AUTOSAR XML (schema 00048)
package /VehicleProject
  system System
package /NM
  nm config NmConfig: can-nm-cluster-coupling=coupled-cluster=[TC37X_VCU_CAN00_CAN, TC37X_VCU_CAN01_CAN]
    can nm cluster TC37X_VCU_CAN00_CAN: communication-cluster=TC37X_VCU_CAN00, nm-channel-id=0, nm-msg-cycle-time=0.5, nm-network-timeout=2, nm-repeat-message-time=1.5, nm-user-data-length=6, nm-wait-bus-sleep-time=2
      can nm node GWM: nm-if-ecu=GWM_CAN, nm-node-id=28, rx-nm-pdu=VCU_Tx_51Ch_NM_oTC37X_VCU_CAN00, tx-nm-pdu=VCU_Rx_500h_NM_oTC37X_VCU_CAN00, nm-msg-cycle-offset=0, nm-msg-reduced-time=0.32, nm-range-config={lower-can-id=1024, upper-can-id=1151}
      can nm node Tester: nm-if-ecu=Tester_CAN, nm-node-id=28, nm-passive-mode-enabled=true, nm-msg-cycle-offset=0, nm-msg-reduced-time=0.32, nm-range-config={lower-can-id=1024, upper-can-id=1151}
      can nm node VCU: controller=CT_TC37X_VCU_CAN00, nm-if-ecu=VCU_CAN, nm-node-id=28, rx-nm-pdu=VCU_Rx_500h_NM_oTC37X_VCU_CAN00, tx-nm-pdu=VCU_Tx_51Ch_NM_oTC37X_VCU_CAN00, nm-msg-cycle-offset=0, nm-msg-reduced-time=0.32, nm-range-config={lower-can-id=1024, upper-can-id=1151}
    can nm cluster TC37X_VCU_CAN01_CAN: communication-cluster=TC37X_VCU_CAN01, nm-channel-id=1, nm-msg-cycle-time=0.5, nm-network-timeout=2, nm-repeat-message-time=1.5, nm-user-data-length=6, nm-wait-bus-sleep-time=2
      can nm node GWM: nm-if-ecu=GWM_CAN, nm-node-id=28, rx-nm-pdu=VCU_Tx_51Ch_NM_oTC37X_VCU_CAN01, tx-nm-pdu=VCU_Rx_500h_NM_oTC37X_VCU_CAN01, nm-msg-cycle-offset=0, nm-msg-reduced-time=0.32, nm-range-config={lower-can-id=1024, upper-can-id=1151}
      can nm node Tester: nm-if-ecu=Tester_CAN, nm-node-id=28, nm-passive-mode-enabled=true, nm-msg-cycle-offset=0, nm-msg-reduced-time=0.32, nm-range-config={lower-can-id=1024, upper-can-id=1151}
      can nm node VCU: controller=CT_TC37X_VCU_CAN01, nm-if-ecu=VCU_CAN, nm-node-id=28, rx-nm-pdu=VCU_Rx_500h_NM_oTC37X_VCU_CAN01, tx-nm-pdu=VCU_Tx_51Ch_NM_oTC37X_VCU_CAN01, nm-msg-cycle-offset=0, nm-msg-reduced-time=0.32, nm-range-config={lower-can-id=1024, upper-can-id=1151}
    nm-if-ecus:
      nm ecu GWM_CAN: nm-node-id-enabled=true, nm-user-data-enabled=true
      nm ecu Tester_CAN: nm-node-id-enabled=true, nm-passive-mode-enabled=true, nm-user-data-enabled=true
      nm ecu VCU_CAN: ecu-instance=VCU, nm-node-id-enabled=true, nm-user-data-enabled=true
package /TP
  can tp config TC37X_VCU_CAN00_CAN: communication-cluster=TC37X_VCU_CAN00, can-tp-ecu{cycle-time-main-function=0.005, ecu-instance=VCU}
    can tp channel TPCH: channel-id=0, channel-mode=FULL-DUPLEX-MODE
    can-tp-connection addressing-format=STANDARD, can-tp-channel=TPCH, data-pdu=Vcu_Uds_Func_Request_Tp_oTC37X_VCU_CAN00, receiver=TN_VCU, ta-type=FUNCTIONAL, tp-sdu=Vcu_Uds_Func_Request_oTC37X_VCU_CAN00, transmitter=TN_Tester:
      ident Vcu_Uds_Func_Request_oTN_Tester
    can-tp-connection addressing-format=STANDARD, can-tp-channel=TPCH, data-pdu=Vcu_Uds_Phy_Request_Tp_oTC37X_VCU_CAN00, flow-control-pdu=Vcu_Uds_Response_Tp_oTC37X_VCU_CAN00, receiver=TN_VCU, ta-type=PHYSICAL, tp-sdu=Vcu_Uds_Phy_Request_oTC37X_VCU_CAN00, transmitter=TN_Tester:
      ident Vcu_Uds_Phy_Request_oTN_VCU
    can-tp-connection addressing-format=STANDARD, can-tp-channel=TPCH, data-pdu=Vcu_Uds_Response_Tp_oTC37X_VCU_CAN00, flow-control-pdu=Vcu_Uds_Phy_Request_Tp_oTC37X_VCU_CAN00, receiver=TN_Tester, ta-type=PHYSICAL, tp-sdu=Vcu_Uds_Response_oTC37X_VCU_CAN00, transmitter=TN_VCU:
      ident Vcu_Uds_Response_oTN_VCU
    can tp node TN_Tester
    can tp node TN_VCU: connector=CN_TC37X_VCU_CAN00
  lin tp config LIN00: communication-cluster=LIN00
    tp address TA_0x0052: tp-address=82
    tp address TA_0x007E: tp-address=126
    tp-connections:
      data-pdu=MasterReq_Tp_oLIN00, lin-tp-n-sdu=MasterReq_oLIN00, multicast=TA_0x007E, receiver=TN_0x0052_GWM, transmitter=TN_Master
      data-pdu=SlaveResp_Tp_oLIN00, flow-control=MasterReq_Tp_oLIN00, lin-tp-n-sdu=SlaveResp_GWM_oLIN00, receiver=TN_Master, transmitter=TN_0x0052_GWM
      data-pdu=MasterReq_Tp_oLIN00, flow-control=SlaveResp_Tp_oLIN00, lin-tp-n-sdu=MasterReq_GWM_oLIN00, receiver=TN_0x0052_GWM, transmitter=TN_Master
    lin tp node TN_0x0052_GWM: tp-address=TA_0x0052
    lin tp node TN_Master: connector=CN_LIN00
package /Cluster
  can cluster TC37X_VCU_CAN00: baudrate=500000, protocol-name=CAN  # VCU_CAN00
    can physical channel CHNL: comm-connectors=CN_TC37X_VCU_CAN00
      frame VCU_Rx_500h_NM_oTC37X_VCU_CAN00: id 0x500, to VCU, frame-length=8, can-addressing-mode=STANDARD
        nm pdu VCU_Rx_500h_NM_oTC37X_VCU_CAN00: length=8, unused-bit-pattern=0
      frame VCU_Tx_51Ch_NM_oTC37X_VCU_CAN00: id 0x51C, from VCU, frame-length=8, can-addressing-mode=STANDARD
        nm pdu VCU_Tx_51Ch_NM_oTC37X_VCU_CAN00: length=8, unused-bit-pattern=0
      frame Vcu_Uds_Func_Request_oTC37X_VCU_CAN00: id 0x700, to VCU, frame-length=8, can-addressing-mode=STANDARD
        n pdu Vcu_Uds_Func_Request_Tp_oTC37X_VCU_CAN00: length=8
      frame Vcu_Uds_Phy_Request_oTC37X_VCU_CAN00: id 0x701, to VCU, frame-length=8, can-addressing-mode=STANDARD
        n pdu Vcu_Uds_Phy_Request_Tp_oTC37X_VCU_CAN00: length=8
      frame Vcu_Uds_Response_oTC37X_VCU_CAN00: id 0x781, from VCU, frame-length=8, can-addressing-mode=STANDARD
        n pdu Vcu_Uds_Response_Tp_oTC37X_VCU_CAN00: length=8
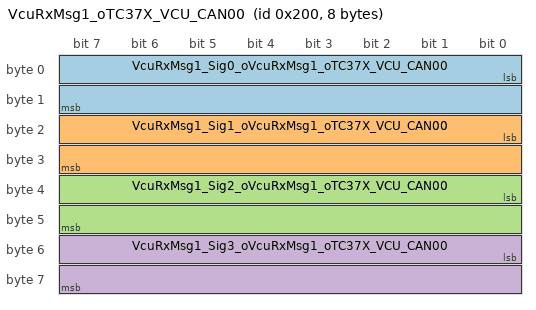
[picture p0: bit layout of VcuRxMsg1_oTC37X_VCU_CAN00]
      frame VcuRxMsg1_oTC37X_VCU_CAN00: id 0x200, to VCU, frame-length=8, can-addressing-mode=STANDARD
        pdu VcuRxMsg1_oTC37X_VCU_CAN00: length=8, minimum-delay=0, transmission-mode-false-timing=cyclic-timing={time-offset=0, time-period=0.5}, transmission-mode-true-timing=cyclic-timing={time-offset=0, time-period=0.5}, unused-bit-pattern=0
          signal VcuRxMsg1_Sig0_oVcuRxMsg1_oTC37X_VCU_CAN00: start 0, 16 bit, little-endian, i-signal-type=PRIMITIVE, init-value=0, base-type=sint16, compu-method=CM_VcuRxMsg1_Sig0, data-constr=DC_VcuRxMsg1_Sig0, transfer-property=PENDING, to VCU
          signal VcuRxMsg1_Sig1_oVcuRxMsg1_oTC37X_VCU_CAN00: start 16, 16 bit, little-endian, i-signal-type=PRIMITIVE, init-value=0, base-type=sint16, compu-method=CM_VcuRxMsg1_Sig1, data-constr=DC_VcuRxMsg1_Sig1, transfer-property=PENDING, to VCU
          signal VcuRxMsg1_Sig2_oVcuRxMsg1_oTC37X_VCU_CAN00: start 32, 16 bit, little-endian, i-signal-type=PRIMITIVE, init-value=0, base-type=sint16, compu-method=CM_VcuRxMsg1_Sig2, data-constr=DC_VcuRxMsg1_Sig2, transfer-property=PENDING, to VCU
          signal VcuRxMsg1_Sig3_oVcuRxMsg1_oTC37X_VCU_CAN00: start 48, 16 bit, little-endian, i-signal-type=PRIMITIVE, init-value=0, base-type=sint16, compu-method=CM_VcuRxMsg1_Sig3, data-constr=DC_VcuRxMsg1_Sig3, transfer-property=PENDING, to VCU
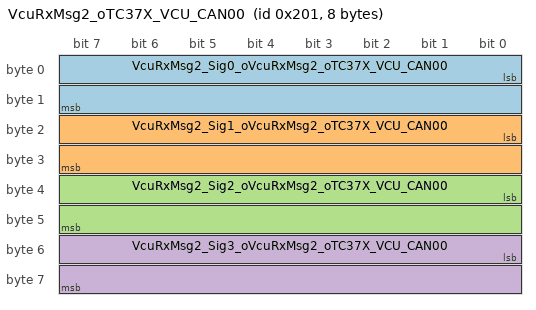
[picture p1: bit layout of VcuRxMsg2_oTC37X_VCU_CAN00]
      frame VcuRxMsg2_oTC37X_VCU_CAN00: id 0x201, to VCU, frame-length=8, can-addressing-mode=STANDARD
        pdu VcuRxMsg2_oTC37X_VCU_CAN00: length=8, minimum-delay=0, transmission-mode-false-timing=cyclic-timing={time-offset=0, time-period=0.5}, transmission-mode-true-timing=cyclic-timing={time-offset=0, time-period=0.5}, unused-bit-pattern=0
          signal VcuRxMsg2_Sig0_oVcuRxMsg2_oTC37X_VCU_CAN00: start 0, 16 bit, little-endian, i-signal-type=PRIMITIVE, init-value=0, base-type=sint16, compu-method=CM_VcuRxMsg2_Sig0, data-constr=DC_VcuRxMsg2_Sig0, transfer-property=PENDING, to VCU
          signal VcuRxMsg2_Sig1_oVcuRxMsg2_oTC37X_VCU_CAN00: start 16, 16 bit, little-endian, i-signal-type=PRIMITIVE, init-value=0, base-type=sint16, compu-method=CM_VcuRxMsg2_Sig1, data-constr=DC_VcuRxMsg2_Sig1, transfer-property=PENDING, to VCU
          signal VcuRxMsg2_Sig2_oVcuRxMsg2_oTC37X_VCU_CAN00: start 32, 16 bit, little-endian, i-signal-type=PRIMITIVE, init-value=0, base-type=sint16, compu-method=CM_VcuRxMsg2_Sig2, data-constr=DC_VcuRxMsg2_Sig2, transfer-property=PENDING, to VCU
          signal VcuRxMsg2_Sig3_oVcuRxMsg2_oTC37X_VCU_CAN00: start 48, 16 bit, little-endian, i-signal-type=PRIMITIVE, init-value=0, base-type=sint16, compu-method=CM_VcuRxMsg2_Sig3, data-constr=DC_VcuRxMsg2_Sig3, transfer-property=PENDING, to VCU
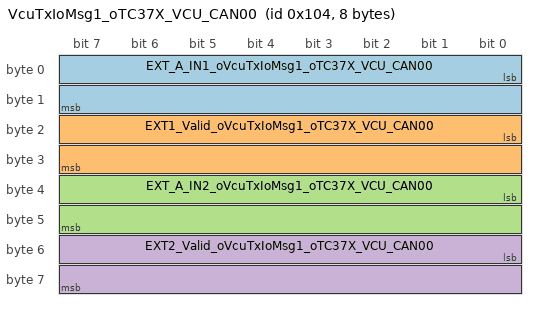
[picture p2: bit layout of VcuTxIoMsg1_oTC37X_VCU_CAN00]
      frame VcuTxIoMsg1_oTC37X_VCU_CAN00: id 0x104, from VCU, frame-length=8, can-addressing-mode=STANDARD
        pdu VcuTxIoMsg1_oTC37X_VCU_CAN00: length=8, minimum-delay=0, transmission-mode-false-timing=cyclic-timing={time-offset=0, time-period=0.5}, transmission-mode-true-timing=cyclic-timing={time-offset=0, time-period=0.5}, unused-bit-pattern=0
          signal EXT_A_IN1_oVcuTxIoMsg1_oTC37X_VCU_CAN00: start 0, 16 bit, little-endian, i-signal-type=PRIMITIVE, init-value=0, base-type=sint16, compu-method=CM_EXT_A_IN1, data-constr=DC_EXT_A_IN1, unit=U_C, transfer-property=PENDING
          signal EXT1_Valid_oVcuTxIoMsg1_oTC37X_VCU_CAN00: start 16, 16 bit, little-endian, i-signal-type=PRIMITIVE, init-value=0, base-type=uint16, compu-method=CM_EXT1_Valid, data-constr=DC_EXT1_Valid, transfer-property=PENDING
          signal EXT_A_IN2_oVcuTxIoMsg1_oTC37X_VCU_CAN00: start 32, 16 bit, little-endian, i-signal-type=PRIMITIVE, init-value=0, base-type=sint16, compu-method=CM_EXT_A_IN2, data-constr=DC_EXT_A_IN2, unit=U_C, transfer-property=PENDING
          signal EXT2_Valid_oVcuTxIoMsg1_oTC37X_VCU_CAN00: start 48, 16 bit, little-endian, i-signal-type=PRIMITIVE, init-value=0, base-type=uint16, compu-method=CM_EXT2_Valid, data-constr=DC_EXT2_Valid, transfer-property=PENDING
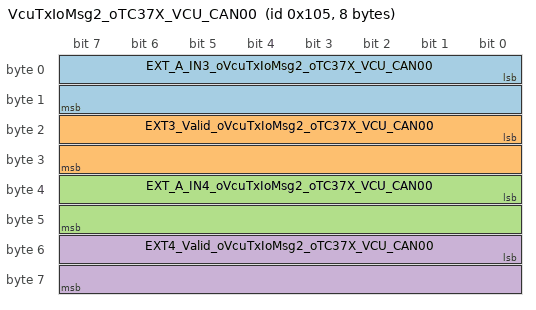
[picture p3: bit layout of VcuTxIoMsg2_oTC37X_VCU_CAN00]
      frame VcuTxIoMsg2_oTC37X_VCU_CAN00: id 0x105, from VCU, frame-length=8, can-addressing-mode=STANDARD
        pdu VcuTxIoMsg2_oTC37X_VCU_CAN00: length=8, minimum-delay=0, transmission-mode-false-timing=cyclic-timing={time-offset=0, time-period=0.5}, transmission-mode-true-timing=cyclic-timing={time-offset=0, time-period=0.5}, unused-bit-pattern=0
          signal EXT_A_IN3_oVcuTxIoMsg2_oTC37X_VCU_CAN00: start 0, 16 bit, little-endian, i-signal-type=PRIMITIVE, init-value=0, base-type=sint16, compu-method=CM_EXT_A_IN3, data-constr=DC_EXT_A_IN3, unit=U_C, transfer-property=PENDING
          signal EXT3_Valid_oVcuTxIoMsg2_oTC37X_VCU_CAN00: start 16, 16 bit, little-endian, i-signal-type=PRIMITIVE, init-value=0, base-type=uint16, compu-method=CM_EXT3_Valid, data-constr=DC_EXT3_Valid, transfer-property=PENDING
          signal EXT_A_IN4_oVcuTxIoMsg2_oTC37X_VCU_CAN00: start 32, 16 bit, little-endian, i-signal-type=PRIMITIVE, init-value=0, base-type=sint16, compu-method=CM_EXT_A_IN4, data-constr=DC_EXT_A_IN4, unit=U_C, transfer-property=PENDING
          signal EXT4_Valid_oVcuTxIoMsg2_oTC37X_VCU_CAN00: start 48, 16 bit, little-endian, i-signal-type=PRIMITIVE, init-value=0, base-type=uint16, compu-method=CM_EXT4_Valid, data-constr=DC_EXT4_Valid, transfer-property=PENDING
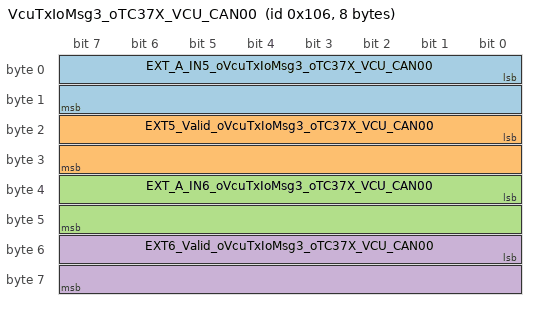
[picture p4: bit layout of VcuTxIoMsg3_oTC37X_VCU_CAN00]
      frame VcuTxIoMsg3_oTC37X_VCU_CAN00: id 0x106, from VCU, frame-length=8, can-addressing-mode=STANDARD
        pdu VcuTxIoMsg3_oTC37X_VCU_CAN00: length=8, minimum-delay=0, transmission-mode-false-timing=cyclic-timing={time-offset=0, time-period=0.5}, transmission-mode-true-timing=cyclic-timing={time-offset=0, time-period=0.5}, unused-bit-pattern=0
          signal EXT_A_IN5_oVcuTxIoMsg3_oTC37X_VCU_CAN00: start 0, 16 bit, little-endian, i-signal-type=PRIMITIVE, init-value=0, base-type=sint16, compu-method=CM_EXT_A_IN5, data-constr=DC_EXT_A_IN5, unit=U_C, transfer-property=PENDING
          signal EXT5_Valid_oVcuTxIoMsg3_oTC37X_VCU_CAN00: start 16, 16 bit, little-endian, i-signal-type=PRIMITIVE, init-value=0, base-type=uint16, compu-method=CM_EXT5_Valid, data-constr=DC_EXT5_Valid, transfer-property=PENDING
          signal EXT_A_IN6_oVcuTxIoMsg3_oTC37X_VCU_CAN00: start 32, 16 bit, little-endian, i-signal-type=PRIMITIVE, init-value=0, base-type=sint16, compu-method=CM_EXT_A_IN6, data-constr=DC_EXT_A_IN6, unit=U_C, transfer-property=PENDING
          signal EXT6_Valid_oVcuTxIoMsg3_oTC37X_VCU_CAN00: start 48, 16 bit, little-endian, i-signal-type=PRIMITIVE, init-value=0, base-type=uint16, compu-method=CM_EXT6_Valid, data-constr=DC_EXT6_Valid, transfer-property=PENDING
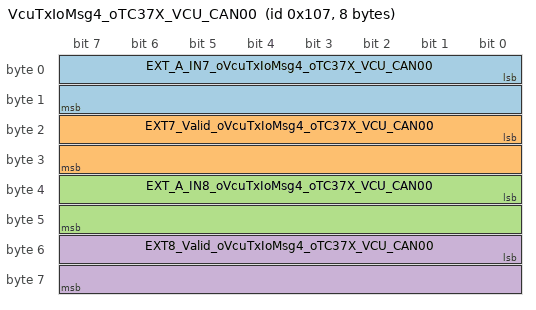
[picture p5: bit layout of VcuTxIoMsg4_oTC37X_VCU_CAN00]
      frame VcuTxIoMsg4_oTC37X_VCU_CAN00: id 0x107, from VCU, frame-length=8, can-addressing-mode=STANDARD
        pdu VcuTxIoMsg4_oTC37X_VCU_CAN00: length=8, minimum-delay=0, transmission-mode-false-timing=cyclic-timing={time-offset=0, time-period=0.5}, transmission-mode-true-timing=cyclic-timing={time-offset=0, time-period=0.5}, unused-bit-pattern=0
          signal EXT_A_IN7_oVcuTxIoMsg4_oTC37X_VCU_CAN00: start 0, 16 bit, little-endian, i-signal-type=PRIMITIVE, init-value=0, base-type=sint16, compu-method=CM_EXT_A_IN7, data-constr=DC_EXT_A_IN7, unit=U_C, transfer-property=PENDING
          signal EXT7_Valid_oVcuTxIoMsg4_oTC37X_VCU_CAN00: start 16, 16 bit, little-endian, i-signal-type=PRIMITIVE, init-value=0, base-type=uint16, compu-method=CM_EXT7_Valid, data-constr=DC_EXT7_Valid, transfer-property=PENDING
          signal EXT_A_IN8_oVcuTxIoMsg4_oTC37X_VCU_CAN00: start 32, 16 bit, little-endian, i-signal-type=PRIMITIVE, init-value=0, base-type=sint16, compu-method=CM_EXT_A_IN8, data-constr=DC_EXT_A_IN8, unit=U_C, transfer-property=PENDING
          signal EXT8_Valid_oVcuTxIoMsg4_oTC37X_VCU_CAN00: start 48, 16 bit, little-endian, i-signal-type=PRIMITIVE, init-value=0, base-type=uint16, compu-method=CM_EXT8_Valid, data-constr=DC_EXT8_Valid, transfer-property=PENDING
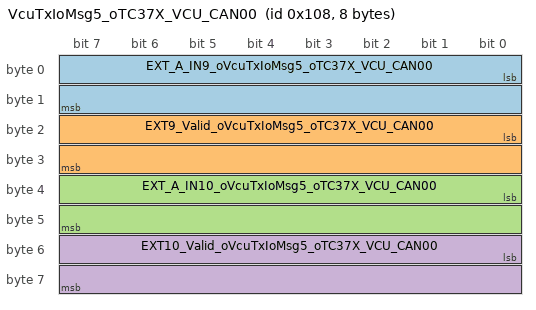
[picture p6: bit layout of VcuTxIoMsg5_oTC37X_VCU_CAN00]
      frame VcuTxIoMsg5_oTC37X_VCU_CAN00: id 0x108, from VCU, frame-length=8, can-addressing-mode=STANDARD
        pdu VcuTxIoMsg5_oTC37X_VCU_CAN00: length=8, minimum-delay=0, transmission-mode-false-timing=cyclic-timing={time-offset=0, time-period=0.5}, transmission-mode-true-timing=cyclic-timing={time-offset=0, time-period=0.5}, unused-bit-pattern=0
          signal EXT_A_IN9_oVcuTxIoMsg5_oTC37X_VCU_CAN00: start 0, 16 bit, little-endian, i-signal-type=PRIMITIVE, init-value=0, base-type=sint16, compu-method=CM_EXT_A_IN9, data-constr=DC_EXT_A_IN9, unit=U_C, transfer-property=PENDING
          signal EXT9_Valid_oVcuTxIoMsg5_oTC37X_VCU_CAN00: start 16, 16 bit, little-endian, i-signal-type=PRIMITIVE, init-value=0, base-type=uint16, compu-method=CM_EXT9_Valid, data-constr=DC_EXT9_Valid, transfer-property=PENDING
          signal EXT_A_IN10_oVcuTxIoMsg5_oTC37X_VCU_CAN00: start 32, 16 bit, little-endian, i-signal-type=PRIMITIVE, init-value=0, base-type=sint16, compu-method=CM_EXT_A_IN10, data-constr=DC_EXT_A_IN10, unit=U_C, transfer-property=PENDING
          signal EXT10_Valid_oVcuTxIoMsg5_oTC37X_VCU_CAN00: start 48, 16 bit, little-endian, i-signal-type=PRIMITIVE, init-value=0, base-type=uint16, compu-method=CM_EXT10_Valid, data-constr=DC_EXT10_Valid, transfer-property=PENDING
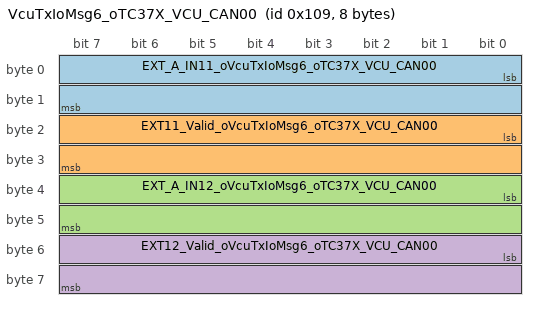
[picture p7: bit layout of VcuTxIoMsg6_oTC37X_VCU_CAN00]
      frame VcuTxIoMsg6_oTC37X_VCU_CAN00: id 0x109, from VCU, frame-length=8, can-addressing-mode=STANDARD
        pdu VcuTxIoMsg6_oTC37X_VCU_CAN00: length=8, minimum-delay=0, transmission-mode-false-timing=cyclic-timing={time-offset=0, time-period=0.5}, transmission-mode-true-timing=cyclic-timing={time-offset=0, time-period=0.5}, unused-bit-pattern=0
          signal EXT_A_IN11_oVcuTxIoMsg6_oTC37X_VCU_CAN00: start 0, 16 bit, little-endian, i-signal-type=PRIMITIVE, init-value=0, base-type=sint16, compu-method=CM_EXT_A_IN11, data-constr=DC_EXT_A_IN11, unit=U_C, transfer-property=PENDING
          signal EXT11_Valid_oVcuTxIoMsg6_oTC37X_VCU_CAN00: start 16, 16 bit, little-endian, i-signal-type=PRIMITIVE, init-value=0, base-type=uint16, compu-method=CM_EXT11_Valid, data-constr=DC_EXT11_Valid, transfer-property=PENDING
          signal EXT_A_IN12_oVcuTxIoMsg6_oTC37X_VCU_CAN00: start 32, 16 bit, little-endian, i-signal-type=PRIMITIVE, init-value=0, base-type=sint16, compu-method=CM_EXT_A_IN12, data-constr=DC_EXT_A_IN12, unit=U_C, transfer-property=PENDING
          signal EXT12_Valid_oVcuTxIoMsg6_oTC37X_VCU_CAN00: start 48, 16 bit, little-endian, i-signal-type=PRIMITIVE, init-value=0, base-type=uint16, compu-method=CM_EXT12_Valid, data-constr=DC_EXT12_Valid, transfer-property=PENDING
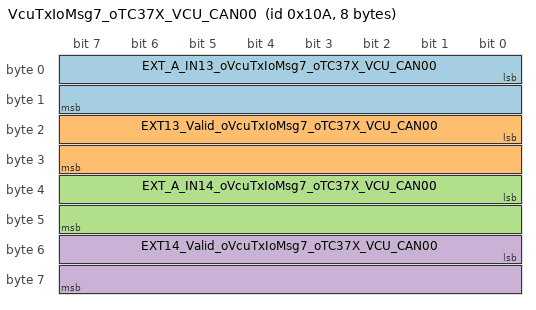
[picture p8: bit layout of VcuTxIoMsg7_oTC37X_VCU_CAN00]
      frame VcuTxIoMsg7_oTC37X_VCU_CAN00: id 0x10A, from VCU, frame-length=8, can-addressing-mode=STANDARD
        pdu VcuTxIoMsg7_oTC37X_VCU_CAN00: length=8, minimum-delay=0, transmission-mode-false-timing=cyclic-timing={time-offset=0, time-period=0.5}, transmission-mode-true-timing=cyclic-timing={time-offset=0, time-period=0.5}, unused-bit-pattern=0
          signal EXT_A_IN13_oVcuTxIoMsg7_oTC37X_VCU_CAN00: start 0, 16 bit, little-endian, i-signal-type=PRIMITIVE, init-value=0, base-type=sint16, compu-method=CM_EXT_A_IN13, data-constr=DC_EXT_A_IN13, unit=U_C, transfer-property=PENDING
          signal EXT13_Valid_oVcuTxIoMsg7_oTC37X_VCU_CAN00: start 16, 16 bit, little-endian, i-signal-type=PRIMITIVE, init-value=0, base-type=uint16, compu-method=CM_EXT13_Valid, data-constr=DC_EXT13_Valid, transfer-property=PENDING
          signal EXT_A_IN14_oVcuTxIoMsg7_oTC37X_VCU_CAN00: start 32, 16 bit, little-endian, i-signal-type=PRIMITIVE, init-value=0, base-type=sint16, compu-method=CM_EXT_A_IN14, data-constr=DC_EXT_A_IN14, unit=U_C, transfer-property=PENDING
          signal EXT14_Valid_oVcuTxIoMsg7_oTC37X_VCU_CAN00: start 48, 16 bit, little-endian, i-signal-type=PRIMITIVE, init-value=0, base-type=uint16, compu-method=CM_EXT14_Valid, data-constr=DC_EXT14_Valid, transfer-property=PENDING
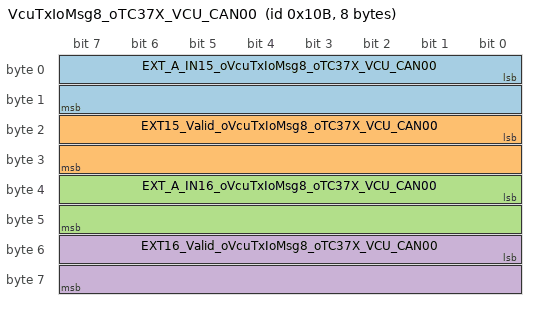
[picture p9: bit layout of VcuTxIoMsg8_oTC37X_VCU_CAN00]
      frame VcuTxIoMsg8_oTC37X_VCU_CAN00: id 0x10B, from VCU, frame-length=8, can-addressing-mode=STANDARD
        pdu VcuTxIoMsg8_oTC37X_VCU_CAN00: length=8, minimum-delay=0, transmission-mode-false-timing=cyclic-timing={time-offset=0, time-period=0.5}, transmission-mode-true-timing=cyclic-timing={time-offset=0, time-period=0.5}, unused-bit-pattern=0
          signal EXT_A_IN15_oVcuTxIoMsg8_oTC37X_VCU_CAN00: start 0, 16 bit, little-endian, i-signal-type=PRIMITIVE, init-value=0, base-type=sint16, compu-method=CM_EXT_A_IN15, data-constr=DC_EXT_A_IN15, unit=U_C, transfer-property=PENDING
          signal EXT15_Valid_oVcuTxIoMsg8_oTC37X_VCU_CAN00: start 16, 16 bit, little-endian, i-signal-type=PRIMITIVE, init-value=0, base-type=uint16, compu-method=CM_EXT15_Valid, data-constr=DC_EXT15_Valid, transfer-property=PENDING
          signal EXT_A_IN16_oVcuTxIoMsg8_oTC37X_VCU_CAN00: start 32, 16 bit, little-endian, i-signal-type=PRIMITIVE, init-value=0, base-type=sint16, compu-method=CM_EXT_A_IN16, data-constr=DC_EXT_A_IN16, unit=U_C, transfer-property=PENDING
          signal EXT16_Valid_oVcuTxIoMsg8_oTC37X_VCU_CAN00: start 48, 16 bit, little-endian, i-signal-type=PRIMITIVE, init-value=0, base-type=uint16, compu-method=CM_EXT16_Valid, data-constr=DC_EXT16_Valid, transfer-property=PENDING
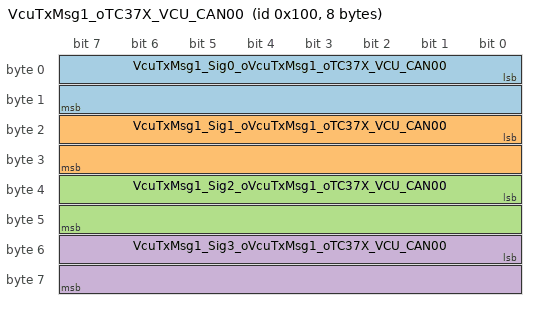
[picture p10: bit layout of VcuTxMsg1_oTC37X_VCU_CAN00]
      frame VcuTxMsg1_oTC37X_VCU_CAN00: id 0x100, from VCU, frame-length=8, can-addressing-mode=STANDARD
        pdu VcuTxMsg1_oTC37X_VCU_CAN00: length=8, minimum-delay=0, transmission-mode-false-timing=cyclic-timing={time-offset=0, time-period=0.5}, transmission-mode-true-timing=cyclic-timing={time-offset=0, time-period=0.5}, unused-bit-pattern=0
          signal VcuTxMsg1_Sig0_oVcuTxMsg1_oTC37X_VCU_CAN00: start 0, 16 bit, little-endian, i-signal-type=PRIMITIVE, init-value=0, base-type=sint16, compu-method=CM_VcuTxMsg1_Sig0, data-constr=DC_VcuTxMsg1_Sig0, transfer-property=PENDING
          signal VcuTxMsg1_Sig1_oVcuTxMsg1_oTC37X_VCU_CAN00: start 16, 16 bit, little-endian, i-signal-type=PRIMITIVE, init-value=0, base-type=sint16, compu-method=CM_VcuTxMsg1_Sig1, data-constr=DC_VcuTxMsg1_Sig1, transfer-property=PENDING
          signal VcuTxMsg1_Sig2_oVcuTxMsg1_oTC37X_VCU_CAN00: start 32, 16 bit, little-endian, i-signal-type=PRIMITIVE, init-value=0, base-type=sint16, compu-method=CM_VcuTxMsg1_Sig2, data-constr=DC_VcuTxMsg1_Sig2, transfer-property=PENDING
          signal VcuTxMsg1_Sig3_oVcuTxMsg1_oTC37X_VCU_CAN00: start 48, 16 bit, little-endian, i-signal-type=PRIMITIVE, init-value=0, base-type=sint16, compu-method=CM_VcuTxMsg1_Sig3, data-constr=DC_VcuTxMsg1_Sig3, transfer-property=PENDING
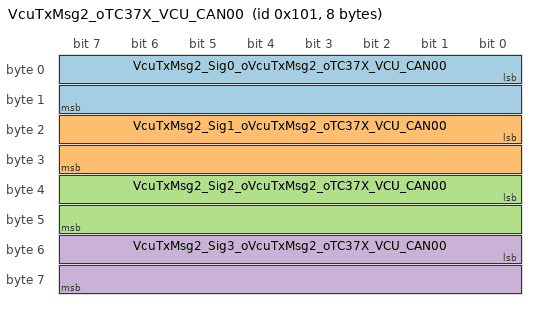
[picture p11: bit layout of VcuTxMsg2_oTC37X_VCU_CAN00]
      frame VcuTxMsg2_oTC37X_VCU_CAN00: id 0x101, from VCU, frame-length=8, can-addressing-mode=STANDARD
        pdu VcuTxMsg2_oTC37X_VCU_CAN00: length=8, minimum-delay=0, transmission-mode-false-timing=cyclic-timing={time-offset=0, time-period=0.5}, transmission-mode-true-timing=cyclic-timing={time-offset=0, time-period=0.5}, unused-bit-pattern=0
          signal VcuTxMsg2_Sig0_oVcuTxMsg2_oTC37X_VCU_CAN00: start 0, 16 bit, little-endian, i-signal-type=PRIMITIVE, init-value=0, base-type=sint16, compu-method=CM_VcuTxMsg2_Sig0, data-constr=DC_VcuTxMsg2_Sig0, transfer-property=PENDING
          signal VcuTxMsg2_Sig1_oVcuTxMsg2_oTC37X_VCU_CAN00: start 16, 16 bit, little-endian, i-signal-type=PRIMITIVE, init-value=0, base-type=sint16, compu-method=CM_VcuTxMsg2_Sig1, data-constr=DC_VcuTxMsg2_Sig1, transfer-property=PENDING
          signal VcuTxMsg2_Sig2_oVcuTxMsg2_oTC37X_VCU_CAN00: start 32, 16 bit, little-endian, i-signal-type=PRIMITIVE, init-value=0, base-type=sint16, compu-method=CM_VcuTxMsg2_Sig2, data-constr=DC_VcuTxMsg2_Sig2, transfer-property=PENDING
          signal VcuTxMsg2_Sig3_oVcuTxMsg2_oTC37X_VCU_CAN00: start 48, 16 bit, little-endian, i-signal-type=PRIMITIVE, init-value=0, base-type=sint16, compu-method=CM_VcuTxMsg2_Sig3, data-constr=DC_VcuTxMsg2_Sig3, transfer-property=PENDING
      frame XCP_Request_oTC37X_VCU_CAN00: id 0x606, to VCU, frame-length=8, can-addressing-mode=STANDARD
        xcp pdu XCP_Request_oTC37X_VCU_CAN00: length=8
      frame XCP_Response_oTC37X_VCU_CAN00: id 0x607, from VCU, frame-length=8, can-addressing-mode=STANDARD
        xcp pdu XCP_Response_oTC37X_VCU_CAN00: length=8
      pdu triggering PT_Vcu_Uds_Func_Request: pdu=Vcu_Uds_Func_Request_oTC37X_VCU_CAN00, to VCU
      pdu triggering PT_Vcu_Uds_Phy_Request: pdu=Vcu_Uds_Phy_Request_oTC37X_VCU_CAN00, to VCU
      pdu triggering PT_Vcu_Uds_Response: pdu=Vcu_Uds_Response_oTC37X_VCU_CAN00, from VCU
  can cluster TC37X_VCU_CAN01: baudrate=500000, protocol-name=CAN  # VCU_CAN01
    can physical channel CHNL: comm-connectors=CN_TC37X_VCU_CAN01
      frame VCU_Rx_500h_NM_oTC37X_VCU_CAN01: id 0x500, to VCU, frame-length=8, can-addressing-mode=STANDARD
        nm pdu VCU_Rx_500h_NM_oTC37X_VCU_CAN01: length=8, unused-bit-pattern=0
      frame VCU_Tx_51Ch_NM_oTC37X_VCU_CAN01: id 0x51C, from VCU, frame-length=8, can-addressing-mode=STANDARD
        nm pdu VCU_Tx_51Ch_NM_oTC37X_VCU_CAN01: length=8, unused-bit-pattern=0
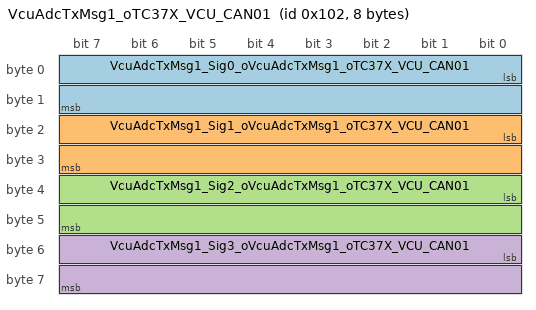
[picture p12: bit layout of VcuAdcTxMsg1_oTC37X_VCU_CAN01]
      frame VcuAdcTxMsg1_oTC37X_VCU_CAN01: id 0x102, from VCU, frame-length=8, can-addressing-mode=STANDARD
        pdu VcuAdcTxMsg1_oTC37X_VCU_CAN01: length=8, minimum-delay=0, transmission-mode-false-timing=cyclic-timing={time-offset=0, time-period=0.5}, transmission-mode-true-timing=cyclic-timing={time-offset=0, time-period=0.5}, unused-bit-pattern=0
          signal VcuAdcTxMsg1_Sig0_oVcuAdcTxMsg1_oTC37X_VCU_CAN01: start 0, 16 bit, little-endian, i-signal-type=PRIMITIVE, init-value=0, base-type=sint16, compu-method=CM_VcuAdcTxMsg1_Sig0, data-constr=DC_VcuAdcTxMsg1_Sig0, transfer-property=PENDING
          signal VcuAdcTxMsg1_Sig1_oVcuAdcTxMsg1_oTC37X_VCU_CAN01: start 16, 16 bit, little-endian, i-signal-type=PRIMITIVE, init-value=0, base-type=sint16, compu-method=CM_VcuAdcTxMsg1_Sig1, data-constr=DC_VcuAdcTxMsg1_Sig1, transfer-property=PENDING
          signal VcuAdcTxMsg1_Sig2_oVcuAdcTxMsg1_oTC37X_VCU_CAN01: start 32, 16 bit, little-endian, i-signal-type=PRIMITIVE, init-value=0, base-type=sint16, compu-method=CM_VcuAdcTxMsg1_Sig2, data-constr=DC_VcuAdcTxMsg1_Sig2, transfer-property=PENDING
          signal VcuAdcTxMsg1_Sig3_oVcuAdcTxMsg1_oTC37X_VCU_CAN01: start 48, 16 bit, little-endian, i-signal-type=PRIMITIVE, init-value=0, base-type=sint16, compu-method=CM_VcuAdcTxMsg1_Sig3, data-constr=DC_VcuAdcTxMsg1_Sig3, transfer-property=PENDING
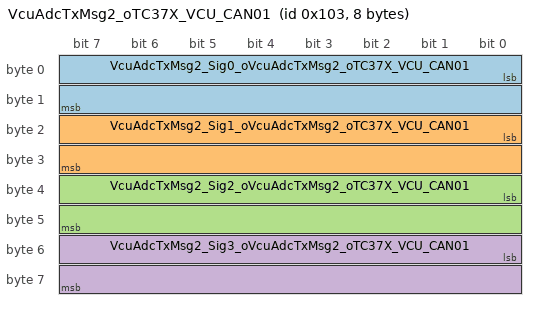
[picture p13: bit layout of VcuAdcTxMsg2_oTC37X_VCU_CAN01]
      frame VcuAdcTxMsg2_oTC37X_VCU_CAN01: id 0x103, from VCU, frame-length=8, can-addressing-mode=STANDARD
        pdu VcuAdcTxMsg2_oTC37X_VCU_CAN01: length=8, minimum-delay=0, transmission-mode-false-timing=cyclic-timing={time-offset=0, time-period=0.5}, transmission-mode-true-timing=cyclic-timing={time-offset=0, time-period=0.5}, unused-bit-pattern=0
          signal VcuAdcTxMsg2_Sig0_oVcuAdcTxMsg2_oTC37X_VCU_CAN01: start 0, 16 bit, little-endian, i-signal-type=PRIMITIVE, init-value=0, base-type=sint16, compu-method=CM_VcuAdcTxMsg2_Sig0, data-constr=DC_VcuAdcTxMsg2_Sig0, transfer-property=PENDING
          signal VcuAdcTxMsg2_Sig1_oVcuAdcTxMsg2_oTC37X_VCU_CAN01: start 16, 16 bit, little-endian, i-signal-type=PRIMITIVE, init-value=0, base-type=sint16, compu-method=CM_VcuAdcTxMsg2_Sig1, data-constr=DC_VcuAdcTxMsg2_Sig1, transfer-property=PENDING
          signal VcuAdcTxMsg2_Sig2_oVcuAdcTxMsg2_oTC37X_VCU_CAN01: start 32, 16 bit, little-endian, i-signal-type=PRIMITIVE, init-value=0, base-type=sint16, compu-method=CM_VcuAdcTxMsg2_Sig2, data-constr=DC_VcuAdcTxMsg2_Sig2, transfer-property=PENDING
          signal VcuAdcTxMsg2_Sig3_oVcuAdcTxMsg2_oTC37X_VCU_CAN01: start 48, 16 bit, little-endian, i-signal-type=PRIMITIVE, init-value=0, base-type=sint16, compu-method=CM_VcuAdcTxMsg2_Sig3, data-constr=DC_VcuAdcTxMsg2_Sig3, transfer-property=PENDING
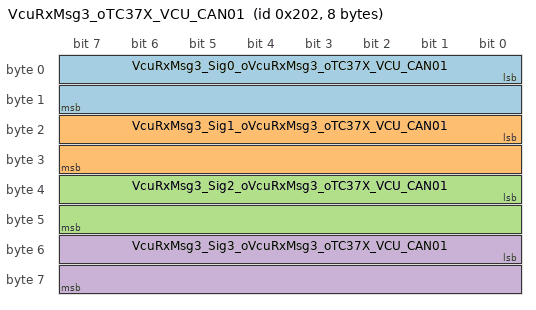
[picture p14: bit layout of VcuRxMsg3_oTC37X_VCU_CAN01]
      frame VcuRxMsg3_oTC37X_VCU_CAN01: id 0x202, to VCU, frame-length=8, can-addressing-mode=STANDARD
        pdu VcuRxMsg3_oTC37X_VCU_CAN01: length=8, minimum-delay=0, transmission-mode-false-timing=cyclic-timing={time-offset=0, time-period=0.5}, transmission-mode-true-timing=cyclic-timing={time-offset=0, time-period=0.5}, unused-bit-pattern=0
          signal VcuRxMsg3_Sig0_oVcuRxMsg3_oTC37X_VCU_CAN01: start 0, 16 bit, little-endian, i-signal-type=PRIMITIVE, init-value=0, base-type=sint16, compu-method=CM_VcuRxMsg3_Sig0, data-constr=DC_VcuRxMsg3_Sig0, transfer-property=PENDING, to VCU
          signal VcuRxMsg3_Sig1_oVcuRxMsg3_oTC37X_VCU_CAN01: start 16, 16 bit, little-endian, i-signal-type=PRIMITIVE, init-value=0, base-type=sint16, compu-method=CM_VcuRxMsg3_Sig1, data-constr=DC_VcuRxMsg3_Sig1, transfer-property=PENDING, to VCU
          signal VcuRxMsg3_Sig2_oVcuRxMsg3_oTC37X_VCU_CAN01: start 32, 16 bit, little-endian, i-signal-type=PRIMITIVE, init-value=0, base-type=sint16, compu-method=CM_VcuRxMsg3_Sig2, data-constr=DC_VcuRxMsg3_Sig2, transfer-property=PENDING, to VCU
          signal VcuRxMsg3_Sig3_oVcuRxMsg3_oTC37X_VCU_CAN01: start 48, 16 bit, little-endian, i-signal-type=PRIMITIVE, init-value=0, base-type=sint16, compu-method=CM_VcuRxMsg3_Sig3, data-constr=DC_VcuRxMsg3_Sig3, transfer-property=PENDING, to VCU
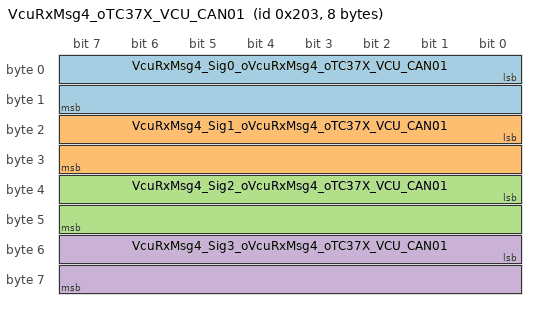
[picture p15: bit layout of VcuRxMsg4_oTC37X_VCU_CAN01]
      frame VcuRxMsg4_oTC37X_VCU_CAN01: id 0x203, to VCU, frame-length=8, can-addressing-mode=STANDARD
        pdu VcuRxMsg4_oTC37X_VCU_CAN01: length=8, minimum-delay=0, transmission-mode-false-timing=cyclic-timing={time-offset=0, time-period=0.5}, transmission-mode-true-timing=cyclic-timing={time-offset=0, time-period=0.5}, unused-bit-pattern=0
          signal VcuRxMsg4_Sig0_oVcuRxMsg4_oTC37X_VCU_CAN01: start 0, 16 bit, little-endian, i-signal-type=PRIMITIVE, init-value=0, base-type=sint16, compu-method=CM_VcuRxMsg4_Sig0, data-constr=DC_VcuRxMsg4_Sig0, transfer-property=PENDING, to VCU
          signal VcuRxMsg4_Sig1_oVcuRxMsg4_oTC37X_VCU_CAN01: start 16, 16 bit, little-endian, i-signal-type=PRIMITIVE, init-value=0, base-type=sint16, compu-method=CM_VcuRxMsg4_Sig1, data-constr=DC_VcuRxMsg4_Sig1, transfer-property=PENDING, to VCU
          signal VcuRxMsg4_Sig2_oVcuRxMsg4_oTC37X_VCU_CAN01: start 32, 16 bit, little-endian, i-signal-type=PRIMITIVE, init-value=0, base-type=sint16, compu-method=CM_VcuRxMsg4_Sig2, data-constr=DC_VcuRxMsg4_Sig2, transfer-property=PENDING, to VCU
          signal VcuRxMsg4_Sig3_oVcuRxMsg4_oTC37X_VCU_CAN01: start 48, 16 bit, little-endian, i-signal-type=PRIMITIVE, init-value=0, base-type=sint16, compu-method=CM_VcuRxMsg4_Sig3, data-constr=DC_VcuRxMsg4_Sig3, transfer-property=PENDING, to VCU
  lin cluster LIN00: baudrate=19200, protocol-name=LIN, protocol-version=LIN21  # /*************************************************************************************/ // // Description: // Created: // Author: // Version: // Vehicle Project: // /*************************************************************************************/
    lin physical channel CHNL: comm-connectors=CN_LIN00
      frame MasterReq_oLIN00: id 0x3C, from VCU, frame-length=8, lin-checksum=CLASSIC
        n pdu MasterReq_Tp_oLIN00: length=8
      frame SlaveResp_oLIN00: id 0x3D, to VCU, frame-length=8, lin-checksum=CLASSIC
        n pdu SlaveResp_Tp_oLIN00: length=8
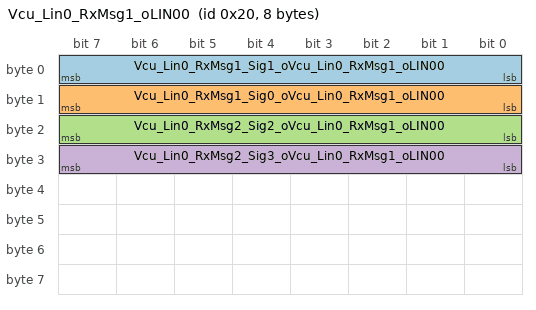
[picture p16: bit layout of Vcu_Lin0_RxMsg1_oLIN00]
      frame Vcu_Lin0_RxMsg1_oLIN00: id 0x20, to VCU, frame-length=8, lin-checksum=ENHANCED
        pdu Vcu_Lin0_RxMsg1_oLIN00: length=8, unused-bit-pattern=255
          signal Vcu_Lin0_RxMsg1_Sig1_oVcu_Lin0_RxMsg1_oLIN00: start 0, 8 bit, little-endian, i-signal-type=PRIMITIVE, init-value=0, base-type=uint8, compu-method=CM_Vcu_Lin0_RxMsg1_Sig1, data-constr=DC_Vcu_Lin0_RxMsg1_Sig1, to VCU
          signal Vcu_Lin0_RxMsg1_Sig0_oVcu_Lin0_RxMsg1_oLIN00: start 8, 8 bit, little-endian, i-signal-type=PRIMITIVE, init-value=0, base-type=uint8, compu-method=CM_Vcu_Lin0_RxMsg1_Sig0, data-constr=DC_Vcu_Lin0_RxMsg1_Sig0, to VCU
          signal Vcu_Lin0_RxMsg2_Sig2_oVcu_Lin0_RxMsg1_oLIN00: start 16, 8 bit, little-endian, i-signal-type=PRIMITIVE, init-value=0, base-type=uint8, compu-method=CM_Vcu_Lin0_RxMsg2_Sig2, data-constr=DC_Vcu_Lin0_RxMsg2_Sig2, to VCU
          signal Vcu_Lin0_RxMsg2_Sig3_oVcu_Lin0_RxMsg1_oLIN00: start 24, 8 bit, little-endian, i-signal-type=PRIMITIVE, init-value=0, base-type=uint8, compu-method=CM_Vcu_Lin0_RxMsg2_Sig3, data-constr=DC_Vcu_Lin0_RxMsg2_Sig3, to VCU
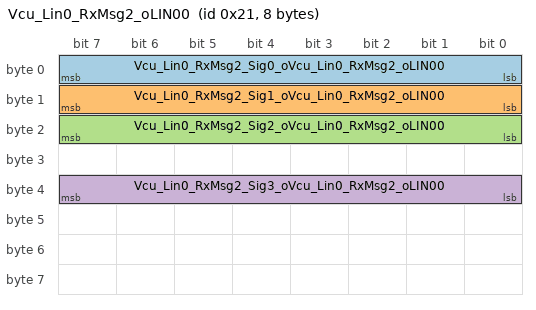
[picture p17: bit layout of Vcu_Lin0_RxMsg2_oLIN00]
      frame Vcu_Lin0_RxMsg2_oLIN00: id 0x21, to VCU, frame-length=8, lin-checksum=ENHANCED
        pdu Vcu_Lin0_RxMsg2_oLIN00: length=8, unused-bit-pattern=255
          signal Vcu_Lin0_RxMsg2_Sig0_oVcu_Lin0_RxMsg2_oLIN00: start 0, 8 bit, little-endian, i-signal-type=PRIMITIVE, init-value=0, base-type=uint8, compu-method=CM_Vcu_Lin0_RxMsg2_Sig0, data-constr=DC_Vcu_Lin0_RxMsg2_Sig0, to VCU
          signal Vcu_Lin0_RxMsg2_Sig1_oVcu_Lin0_RxMsg2_oLIN00: start 8, 8 bit, little-endian, i-signal-type=PRIMITIVE, init-value=0, base-type=uint8, compu-method=CM_Vcu_Lin0_RxMsg2_Sig1, data-constr=DC_Vcu_Lin0_RxMsg2_Sig1, to VCU
          signal Vcu_Lin0_RxMsg2_Sig2_oVcu_Lin0_RxMsg2_oLIN00: start 16, 8 bit, little-endian, i-signal-type=PRIMITIVE, init-value=0, base-type=uint8, compu-method=CM_Vcu_Lin0_RxMsg2_Sig2, data-constr=DC_Vcu_Lin0_RxMsg2_Sig2, to VCU
          signal Vcu_Lin0_RxMsg2_Sig3_oVcu_Lin0_RxMsg2_oLIN00: start 32, 8 bit, little-endian, i-signal-type=PRIMITIVE, init-value=0, base-type=uint8, compu-method=CM_Vcu_Lin0_RxMsg2_Sig3, data-constr=DC_Vcu_Lin0_RxMsg2_Sig3, to VCU
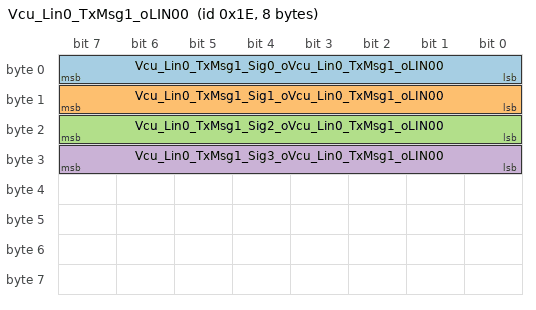
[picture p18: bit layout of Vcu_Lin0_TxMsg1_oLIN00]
      frame Vcu_Lin0_TxMsg1_oLIN00: id 0x1E, from VCU, frame-length=8, lin-checksum=ENHANCED
        pdu Vcu_Lin0_TxMsg1_oLIN00: length=8, unused-bit-pattern=255
          signal Vcu_Lin0_TxMsg1_Sig0_oVcu_Lin0_TxMsg1_oLIN00: start 0, 8 bit, little-endian, i-signal-type=PRIMITIVE, init-value=0, base-type=uint8, compu-method=CM_Vcu_Lin0_TxMsg1_Sig0, data-constr=DC_Vcu_Lin0_TxMsg1_Sig0
          signal Vcu_Lin0_TxMsg1_Sig1_oVcu_Lin0_TxMsg1_oLIN00: start 8, 8 bit, little-endian, i-signal-type=PRIMITIVE, init-value=0, base-type=uint8, compu-method=CM_Vcu_Lin0_TxMsg1_Sig1, data-constr=DC_Vcu_Lin0_TxMsg1_Sig1
          signal Vcu_Lin0_TxMsg1_Sig2_oVcu_Lin0_TxMsg1_oLIN00: start 16, 8 bit, little-endian, i-signal-type=PRIMITIVE, init-value=0, base-type=uint8, compu-method=CM_Vcu_Lin0_TxMsg1_Sig2, data-constr=DC_Vcu_Lin0_TxMsg1_Sig2
          signal Vcu_Lin0_TxMsg1_Sig3_oVcu_Lin0_TxMsg1_oLIN00: start 24, 8 bit, little-endian, i-signal-type=PRIMITIVE, init-value=0, base-type=uint8, compu-method=CM_Vcu_Lin0_TxMsg1_Sig3, data-constr=DC_Vcu_Lin0_TxMsg1_Sig3
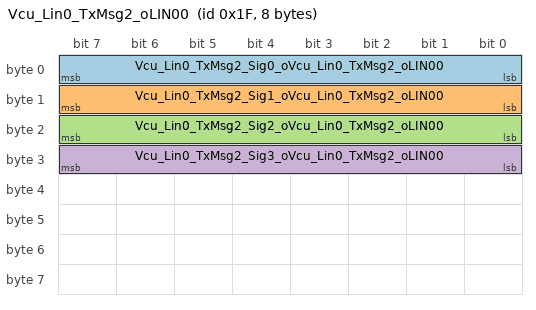
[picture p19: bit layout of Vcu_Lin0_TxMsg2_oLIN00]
      frame Vcu_Lin0_TxMsg2_oLIN00: id 0x1F, from VCU, frame-length=8, lin-checksum=ENHANCED
        pdu Vcu_Lin0_TxMsg2_oLIN00: length=8, unused-bit-pattern=255
          signal Vcu_Lin0_TxMsg2_Sig0_oVcu_Lin0_TxMsg2_oLIN00: start 0, 8 bit, little-endian, i-signal-type=PRIMITIVE, init-value=0, base-type=uint8, compu-method=CM_Vcu_Lin0_TxMsg2_Sig0, data-constr=DC_Vcu_Lin0_TxMsg2_Sig0
          signal Vcu_Lin0_TxMsg2_Sig1_oVcu_Lin0_TxMsg2_oLIN00: start 8, 8 bit, little-endian, i-signal-type=PRIMITIVE, init-value=0, base-type=uint8, compu-method=CM_Vcu_Lin0_TxMsg2_Sig1, data-constr=DC_Vcu_Lin0_TxMsg2_Sig1
          signal Vcu_Lin0_TxMsg2_Sig2_oVcu_Lin0_TxMsg2_oLIN00: start 16, 8 bit, little-endian, i-signal-type=PRIMITIVE, init-value=0, base-type=uint8, compu-method=CM_Vcu_Lin0_TxMsg2_Sig2, data-constr=DC_Vcu_Lin0_TxMsg2_Sig2
          signal Vcu_Lin0_TxMsg2_Sig3_oVcu_Lin0_TxMsg2_oLIN00: start 24, 8 bit, little-endian, i-signal-type=PRIMITIVE, init-value=0, base-type=uint8, compu-method=CM_Vcu_Lin0_TxMsg2_Sig3, data-constr=DC_Vcu_Lin0_TxMsg2_Sig3
      pdu triggering PT_MasterReq: pdu=MasterReq_oLIN00, from VCU
      pdu triggering PT_MasterReq_GWM: pdu=MasterReq_GWM_oLIN00, from VCU
      pdu triggering PT_SlaveResp_GWM: pdu=SlaveResp_GWM_oLIN00, to VCU
      lin schedule table Vcu_Lin0_Schedule: run-mode=RUN-CONTINUOUS
        table-entrys:
          delay=0.02, position-in-table=0, frame-triggering=FT_Vcu_Lin0_TxMsg1
          delay=0.02, position-in-table=1, frame-triggering=FT_Vcu_Lin0_TxMsg2
          delay=0.02, position-in-table=2, frame-triggering=FT_Vcu_Lin0_RxMsg1
          delay=0.02, position-in-table=3, frame-triggering=FT_Vcu_Lin0_RxMsg2
package /ECU
  ecu instance VCU: associated-com-i-pdu-group=[VCU_oLIN00_Rx, VCU_oLIN00_Tx, VCU_oTC37X_VCU_CAN00_Rx, VCU_oTC37X_VCU_CAN00_Tx, VCU_oTC37X_VCU_CAN01_Rx, VCU_oTC37X_VCU_CAN01_Tx]
    can communication controller CT_TC37X_VCU_CAN00
    can communication controller CT_TC37X_VCU_CAN01
    lin master CT_LIN00: protocol-version=LIN21, time-base=0.005, time-base-jitter=0.0001
    can communication connector CN_TC37X_VCU_CAN00: comm-controller=CT_TC37X_VCU_CAN00
    can communication connector CN_TC37X_VCU_CAN01: comm-controller=CT_TC37X_VCU_CAN01
    lin communication connector CN_LIN00: comm-controller=CT_LIN00
package /Gateway
  gateway VCU: ecu=VCU
package /IPDUGroup
  6 x i signal i pdu group:
    VCU_oLIN00_Rx: communication-direction=IN, i-signal-i-pdus=[Vcu_Lin0_RxMsg1_oLIN00, Vcu_Lin0_RxMsg2_oLIN00]
    VCU_oLIN00_Tx: communication-direction=OUT, i-signal-i-pdus=[Vcu_Lin0_TxMsg1_oLIN00, Vcu_Lin0_TxMsg2_oLIN00]
    VCU_oTC37X_VCU_CAN00_Rx: communication-direction=IN, i-signal-i-pdus=[VcuRxMsg1_oTC37X_VCU_CAN00, VcuRxMsg2_oTC37X_VCU_CAN00]
    VCU_oTC37X_VCU_CAN00_Tx: communication-direction=OUT
      i-signal-i-pdus:
        VcuTxIoMsg{1..8}_oTC37X_VCU_CAN00
        VcuTxMsg1_oTC37X_VCU_CAN00
        VcuTxMsg2_oTC37X_VCU_CAN00
    VCU_oTC37X_VCU_CAN01_Rx: communication-direction=IN, i-signal-i-pdus=[VcuRxMsg3_oTC37X_VCU_CAN01, VcuRxMsg4_oTC37X_VCU_CAN01]
    VCU_oTC37X_VCU_CAN01_Tx: communication-direction=OUT, i-signal-i-pdus=[VcuAdcTxMsg1_oTC37X_VCU_CAN01, VcuAdcTxMsg2_oTC37X_VCU_CAN01]
package /PDU
  dcm i pdu MasterReq_GWM_oLIN00: length=8, diag-pdu-type=DIAG-REQUEST
  dcm i pdu MasterReq_oLIN00: length=8, diag-pdu-type=DIAG-REQUEST
  dcm i pdu SlaveResp_GWM_oLIN00: length=8, diag-pdu-type=DIAG-RESPONSE
  dcm i pdu Vcu_Uds_Func_Request_oTC37X_VCU_CAN00: length=7, diag-pdu-type=DIAG-REQUEST
  dcm i pdu Vcu_Uds_Phy_Request_oTC37X_VCU_CAN00: length=8, diag-pdu-type=DIAG-REQUEST
  dcm i pdu Vcu_Uds_Response_oTC37X_VCU_CAN00: length=8, diag-pdu-type=DIAG-RESPONSE
